# LPC54102_cm0plus register map
Vendor: nxp.com; File version: 1.0
CPU: CM0PLUS r0p0, little endian, no MPU, no FPU, VTOR, 2 interrupt priority bits
Registers are 32-bit, read-write, reset 0x0 unless marked. A register's access mark holds for its fields unless they carry their own. Offsets are from the block's base; [hi:lo] are bit positions; {n}, {i} and the like mark numbered series.

## RIT — Repetitive Interrupt Timer
Base 0x40070000
0x00 COMPVAL reset 0xFFFFFFFF — Compare value LSB register. Holds the 32 LSBs of the compare value.
  [31:0] RICOMP — Compare register. Holds the 32 LSBs of the value which is compared to the counter.
0x04 MASK — Mask LSB register. This register holds the 32 LSB s of the mask value. A 1 written to any bit will force the compare to be true for the corresponding bit of the counter and compare register.
  [31:0] RIMASK — Mask register. This register holds the 32 LSBs of the mask value. A one written to any bit overrides the result of the comparison for the corresponding bit of the counter and compare register (causes the comparison of the register bits to be always true).
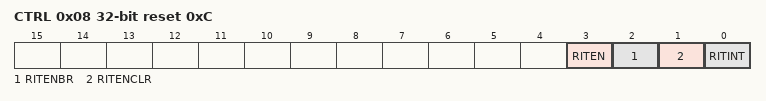
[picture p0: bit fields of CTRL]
0x08 CTRL reset 0xC — Control register.
  [3] RITEN — Timer enable.
    0=TIMER_DISABLED; 1=TIMER_ENABLED (Timer enabled. This can be overruled by a debug halt if enabled in bit 2.)
  [2] RITENBR — Timer enable for debug
    0=DEBUG (Debug has no effect on the timer operation.); 1=HALT (The timer is halted when the processor is halted for debugging.)
  [1] RITENCLR — Timer enable clear
    0=NOCLEAR (The timer will not be cleared to 0.); 1=CLEAR (The timer will be cleared to 0 whenever the counter value equals the masked compare value specified by the contents of COMPVAL/COMPVAL_H and MASK/MASK_H registers. This will occur on the same clock that sets the interrupt flag.)
  [0] RITINT — Interrupt flag
    0=NOMTCH (The counter value does not equal the masked compare value.); 1=MATCH (This bit is set to 1 by hardware whenever the counter value equals the masked compare value specified by the contents of RICOMPVAL and RIMASK registers. Writing a 1 to this bit will clear it to 0. Writing a 0 has no effect.)
0x0C COUNTER — Counter LSB register. 32 LSBs of the counter.
  [31:0] RICOUNTER — 32 LSBs of the up counter. Counts continuously unless RITEN bit in CTRL register is cleared or debug mode is entered (if enabled by the RITNEBR bit in RICTRL). Can be loaded to any value in software.
0x10 COMPVAL_H reset 0xFFFF — Compare value MSB register. Holds the 16 MSBs of the compare value.
  [15:0] RICOMP — Compare value MSB register. Holds the 16 MSBs of the value which is compared to the counter.
0x14 MASK_H — Mask MSB register. This register holds the 16 MSBs of the mask value. A 1 written to any bit will force a compare on the corresponding bit of the counter and compare register.
  [15:0] RIMASK — Mask register. This register holds the 16 MSBs of the mask value. A one written to any bit overrides the result of the comparison for the corresponding bit of the counter and compare register (causes the comparison of the register bits to be always true).
0x1C COUNTER_H — Counter MSB register. 16 MSBs of the counter.
  [15:0] RICOUNTER — 16 LSBs of the up counter. Counts continuously unless RITEN bit in RICTRL register is cleared or debug mode is entered (if enabled by the RITNEBR bit in RICTRL). Can be loaded to any value in software.

## SysTick — System timer
Base 0xE000E010; register names take the prefix SYST_
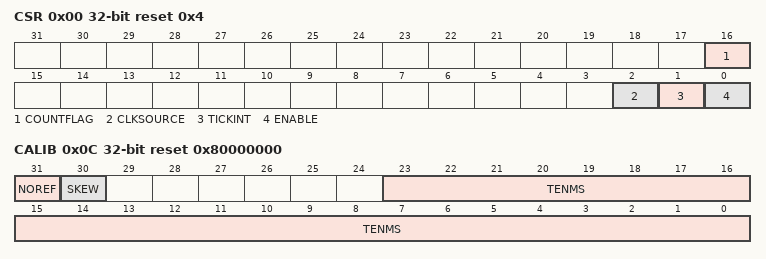
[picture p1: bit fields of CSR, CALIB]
0x00 CSR reset 0x4 — SysTick Control and Status Register
  [16] COUNTFLAG
  [2] CLKSOURCE
    0=external clock; 1=processor clock
  [1] TICKINT
    0=counting down to 0 does not assert the SysTick exception request; 1=counting down to 0 asserts the SysTick exception request
  [0] ENABLE
    0=counter disabled; 1=counter enabled
0x04 RVR — SysTick Reload Value Register
  [23:0] RELOAD — Value to load into the SysTick Current Value Register when the counter reaches 0
0x08 CVR — SysTick Current Value Register
  [23:0] CURRENT — Current value at the time the register is accessed
0x0C CALIB ro reset 0x80000000 — SysTick Calibration Value Register
  [31] NOREF
    0=The reference clock is provided; 1=The reference clock is not provided
  [30] SKEW
    0=10ms calibration value is exact; 1=10ms calibration value is inexact, because of the clock frequency
  [23:0] TENMS — Reload value to use for 10ms timing

## NVIC — Nested Vectored Interrupt Controller
Base 0xE000E100
{0x0+4i} NVICISER{i} (i=0..3) — Interrupt Set Enable Register n
  [31:0] SETENA — Interrupt set enable bits
{0x80+4i} NVICICER{i} (i=0..3) — Interrupt Clear Enable Register n
  [31:0] CLRENA — Interrupt clear-enable bits
{0x100+4i} NVICISPR{i} (i=0..3) — Interrupt Set Pending Register n
  [31:0] SETPEND — Interrupt set-pending bits
{0x180+4i} NVICICPR{i} (i=0..3) — Interrupt Clear Pending Register n
  [31:0] CLRPEND — Interrupt clear-pending bits
{0x200+4i} NVICIABR{i} (i=0..3) — Interrupt Active bit Register n
  [31:0] ACTIVE — Interrupt active flags
{0x300+i} NVICIP{i} 8-bit (i=0..105) — Interrupt Priority Register n
  [7:0] PRI{i} — Priority of interrupt {i}
0xE00 NVICSTIR — Software Trigger Interrupt Register
  [8:0] INTID — Interrupt ID of the interrupt to trigger, in the range 0-239. For example, a value of 0x03 specifies interrupt IRQ3.
